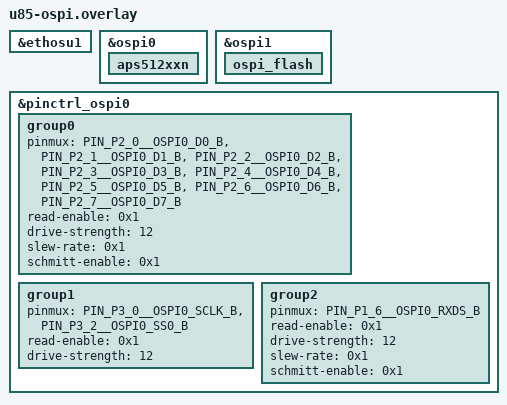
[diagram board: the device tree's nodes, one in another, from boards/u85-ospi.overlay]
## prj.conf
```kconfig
CONFIG_CPP=y
CONFIG_STD_CPP17=y
CONFIG_TENSORFLOW_LITE_MICRO=y
CONFIG_CMSIS_DSP=y
CONFIG_CMSIS_DSP_BASICMATH=y
CONFIG_CMSIS_DSP_COMPLEXMATH=y
CONFIG_CMSIS_DSP_TRANSFORM=y
CONFIG_ARM_ETHOS_U=y
CONFIG_HEAP_MEM_POOL_SIZE=16384
CONFIG_EVENTS=y

CONFIG_AUDIO=y
CONFIG_AUDIO_DMIC=y
CONFIG_TINYCRYPT=y
CONFIG_TINYCRYPT_SHA256=y

CONFIG_SERIAL=y
CONFIG_UART_INTERRUPT_DRIVEN=y
CONFIG_UART_LINE_CTRL=y
CONFIG_CONSOLE=y
CONFIG_UART_CONSOLE=y
CONFIG_PRINTK=y
CONFIG_LOG=y
CONFIG_LOG_MODE_IMMEDIATE=y
CONFIG_ARM_ETHOS_U_LOG_LEVEL_NONE=y

CONFIG_USB_DEVICE_STACK_NEXT=y
CONFIG_USBD_CDC_ACM_CLASS=y
CONFIG_USBD_LOG_LEVEL_WRN=y
CONFIG_UDC_DRIVER_LOG_LEVEL_WRN=y
CONFIG_USBD_CDC_ACM_LOG_LEVEL_ERR=y

CONFIG_BUILD_OUTPUT_HEX_GAP_FILL=n
CONFIG_BUILD_OUTPUT_S19_GAP_FILL=n

CONFIG_REQUIRES_FULL_LIBC=y
CONFIG_NEWLIB_LIBC=y
CONFIG_REQUIRES_FULL_LIBCPP=y
CONFIG_NEWLIB_LIBC_MIN_REQUIRED_HEAP_SIZE=8192
CONFIG_MAIN_STACK_SIZE=32768
```

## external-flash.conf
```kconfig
# Enable the frozen onboard ISSI driver/XIP initialization only.
CONFIG_FLASH=y
CONFIG_ALIF_OSPI_FLASH_XIP=y
```

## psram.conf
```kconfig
CONFIG_MEMC=y
CONFIG_MEMC_OSPI_ALIF=y
CONFIG_MEMC_ALIF_OSPI_APS512XXN=y
```

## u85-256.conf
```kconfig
CONFIG_ARM_ETHOS_U55_256=n
CONFIG_ARM_ETHOS_U85_256=y
```

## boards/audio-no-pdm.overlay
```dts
/* Build-only audio NONE personality: do not initialize the board PDM device. */
&pdm {
	status = "disabled";
};
```

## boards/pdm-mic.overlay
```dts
/*
 * Enable the pinned Alif PDM/DMIC peripheral for the DevKit microphone pair.
 * Channel selection remains an application-level contract.
 */
/ {
	aliases {
		pdm-audio = &pdm;
	};
};

&pdm {
	status = "okay";
};
```

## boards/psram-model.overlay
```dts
#include <zephyr/dt-bindings/memory-attr/memory-attr-arm.h>

/ {
	psram_model_memory: memory@a0000000 {
		compatible = "zephyr,memory-region";
		reg = <0xa0000000 0x04000000>;
		zephyr,memory-region = "PSRAM_MODEL";
		zephyr,memory-region-flags = "rw";
		zephyr,memory-attr = <DT_MEM_ARM_MPU_RAM_NOCACHE>;
	};
};
```

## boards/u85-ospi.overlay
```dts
/* Enable the on-board U85 and the OSPI devices required by the H1 image. */
&ethosu1 {
	status = "okay";
};

&ospi0 {
	status = "okay";
	aps512xxn {
		status = "okay";
	};
};

&ospi1 {
	status = "okay";
	ospi_flash {
		status = "okay";
	};
};

/* Copyright (C) Alif Semiconductor - All Rights Reserved.
 * Use, distribution and modification of this code is permitted under the
 * terms stated in the Alif Semiconductor Software License Agreement.
 *
 * Historical E8 DK PSRAM pin groups from the accepted ospi-psram snippet
 * (e8_dk_ospi0.overlay, SHA-256
 * 2add03d875047de8df6faa1a5b132625d34051ddc3e2ba87365804d300ab6d93).
 */
&pinctrl_ospi0 {
	group0 {
		pinmux = < PIN_P2_0__OSPI0_D0_B >,
			 < PIN_P2_1__OSPI0_D1_B >,
			 < PIN_P2_2__OSPI0_D2_B >,
			 < PIN_P2_3__OSPI0_D3_B >,
			 < PIN_P2_4__OSPI0_D4_B >,
			 < PIN_P2_5__OSPI0_D5_B >,
			 < PIN_P2_6__OSPI0_D6_B >,
			 < PIN_P2_7__OSPI0_D7_B >;
		read-enable = <0x1>;
		drive-strength = <12>;
		slew-rate = <0x1>;
		schmitt-enable = <0x1>;
	};
	group1 {
		pinmux = < PIN_P3_0__OSPI0_SCLK_B >,
			 < PIN_P3_2__OSPI0_SS0_B >;
		read-enable = <0x1>;
		drive-strength = <12>;
	};
	group2 {
		pinmux = < PIN_P1_6__OSPI0_RXDS_B >;
		read-enable = <0x1>;
		drive-strength = <12>;
		slew-rate = <0x1>;
		schmitt-enable = <0x1>;
	};
};
```

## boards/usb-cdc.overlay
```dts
/*
 * Native E8 USB-C application channel. This is the pinned sdk-alif CDC ACM
 * sample mechanism, with larger lossless application FIFOs.
 */
#include <dt-bindings/misc/alif_aipm_common.h>

&aipm_run_default {
	phy-pwr-gating = <ALIF_PHY_GATE_USB_MASK>;
};

ns: &ns {
	status = "okay";
};

zephyr_udc0: &usb {
	status = "okay";
};

&zephyr_udc0 {
	cdc_acm_uart0: cdc_acm_uart0 {
		compatible = "zephyr,cdc-acm-uart";
		label = "BirdNET H1 application channel";
		rx-fifo-size = <8192>;
		tx-fifo-size = <8192>;
		hw-flow-control;
	};
};
```

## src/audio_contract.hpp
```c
#pragma once

#include <cstddef>
#include <cstdint>

constexpr uint32_t H1_MIC_SAMPLE_RATE_HZ = 32000;
constexpr uint32_t H1_MIC_WINDOW_SAMPLES = 96000;
constexpr uint32_t H1_MIC_STRIDE_SAMPLES = 32000;
constexpr uint32_t H1_MIC_OVERLAP_SAMPLES = 64000;
constexpr uint32_t H1_MIC_RING_SAMPLES = 160000;
constexpr uint32_t H1_MIC_BLOCK_BYTES = 2048;
constexpr uint32_t H1_MIC_BLOCK_SAMPLES = H1_MIC_BLOCK_BYTES / sizeof(int16_t);
constexpr uint32_t H1_MIC_SLAB_BLOCKS = 8;
constexpr uint32_t H1_MIC_WINDOW_BYTES = H1_MIC_WINDOW_SAMPLES * sizeof(int16_t);
constexpr uint32_t H1_MIC_PCM_CHUNK_MAX_BYTES = 1024;
constexpr uint64_t H1_MIC_LATEST_WINDOW = UINT64_MAX;

static_assert(H1_MIC_WINDOW_SAMPLES == 3 * H1_MIC_SAMPLE_RATE_HZ);
static_assert(H1_MIC_STRIDE_SAMPLES == H1_MIC_SAMPLE_RATE_HZ);
static_assert(H1_MIC_WINDOW_SAMPLES - H1_MIC_STRIDE_SAMPLES ==
	      H1_MIC_OVERLAP_SAMPLES);
static_assert(H1_MIC_RING_SAMPLES >=
	      H1_MIC_WINDOW_SAMPLES + H1_MIC_STRIDE_SAMPLES);
static_assert(H1_MIC_BLOCK_BYTES % sizeof(int16_t) == 0);

enum class H1MicMode : uint32_t {
	Off = 0,
	CaptureOnly = 1,
	WindowValidate = 2,
	H1Single = 3,
};

enum class H1MicState : uint32_t {
	Off = 0,
	Starting = 1,
	Capture = 2,
	WindowReady = 3,
	Error = 4,
};

enum class H1MicInferenceState : uint32_t {
	Idle = 0,
	Running = 1,
	ResultReady = 2,
};

enum class H1MicError : int32_t {
	None = 0,
	NotInitialized = 1,
	AlreadyRunning = 2,
	InvalidMode = 3,
	TriggerStart = 4,
	TriggerStop = 5,
	ReadTimeout = 6,
	ReadFailure = 7,
	InvalidBlockSize = 8,
	Fifo = 9,
	SlabExhausted = 10,
	DriverQueueOverrun = 11,
	Sequence = 12,
	RingFrontier = 13,
	NoCompleteWindow = 14,
	WindowNotRetained = 15,
	ModeDisallowsOperation = 16,
	NoSelectedWindow = 17,
};

struct H1PcmStatistics {
	uint64_t sampleCount;
	int16_t minimum;
	int16_t maximum;
	int64_t sum;
	uint64_t sumSquares;
	uint64_t positiveClippingCount;
	uint64_t negativeClippingCount;
	uint64_t zeroCount;
	uint32_t maximumAdjacentJump;
};

struct H1SelectedWindowInfo {
	bool valid;
	uint64_t sequence;
	uint64_t startSample;
	uint64_t endSample;
	uint32_t physicalStartIndex;
	bool wraps;
	uint32_t crc32;
	char sha256[65];
	H1PcmStatistics statistics;
};

struct H1MicStatusSnapshot {
	bool initialized;
	bool running;
	H1MicMode mode;
	H1MicState state;
	H1MicInferenceState inferenceState;
	H1MicError lastError;
	int32_t initStatus;
	int32_t lastDriverStatus;
	uint64_t driverPublishedBlocks;
	uint64_t consumedBlocks;
	uint64_t expectedSequence;
	uint64_t sequenceFaults;
	uint64_t fifoErrors;
	uint64_t slabMisses;
	uint64_t driverQueueOverruns;
	uint64_t readTimeouts;
	uint64_t invalidBlockSizes;
	uint32_t queueOccupancy;
	uint32_t queueHighWater;
	uint32_t slabUsed;
	uint32_t slabHighWater;
	uint64_t firstPublishCycles;
	uint64_t lastPublishCycles;
	uint32_t timingClockHz;
	uint64_t totalSamplesCommitted;
	uint64_t oldestRetainedSample;
	uint32_t ringWriteIndex;
	uint64_t ringFrontierFaults;
	uint64_t completeWindows;
	uint64_t latestWindowSequence;
	uint64_t latestWindowStartSample;
	uint64_t latestWindowEndSample;
	uint64_t windowGeometryFaults;
	H1PcmStatistics captureStatistics;
	H1SelectedWindowInfo selectedWindow;
};

const char *h1MicModeName(H1MicMode mode);
const char *h1MicStateName(H1MicState state);
const char *h1MicInferenceStateName(H1MicInferenceState state);
const char *h1MicErrorName(H1MicError error);
```

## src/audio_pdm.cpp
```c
#include "audio_pdm.hpp"

#include "audio_pdm_driver_hooks.h"
#include "model_storage.hpp"
#include "pcm_ring.hpp"
#include "run_state.hpp"
#include "sha256.hpp"
#include "sliding_window.hpp"

#include <cerrno>
#include <climits>
#include <cstddef>
#include <cstdint>
#include <cstring>

#include <zephyr/audio/dmic.h>
#include <zephyr/device.h>
#include <zephyr/devicetree.h>
#include <zephyr/drivers/pdm/pdm_alif.h>
#include <zephyr/kernel.h>
#include <zephyr/sys/atomic.h>
#include <zephyr/sys/time_units.h>

namespace {
constexpr uint8_t kChannel = 4;
constexpr uint32_t kChannelMap = PDM_MASK_CHANNEL_4;
constexpr uint32_t kPhase = 0x0000001f;
constexpr uint32_t kGain = 0x0000000d;
constexpr uint32_t kPeakDetectThreshold = 0x00060002;
constexpr uint32_t kPeakDetectInterval = 0x0004002d;
constexpr uint32_t kIirCoefficient = 0x00000004;
constexpr int32_t kReadTimeoutMs = 500;
constexpr size_t kThreadStackBytes = 4096;

constexpr uint32_t kFirCoefficients[PDM_MAX_FIR_COEFFICIENT] = {
	0x00000001, 0x00000003, 0x00000003, 0x000007f4, 0x00000004,
	0x000007ed, 0x000007f5, 0x000007f4, 0x000007d3, 0x000007fe,
	0x000007bc, 0x000007e5, 0x000007d9, 0x00000793, 0x00000029,
	0x0000072c, 0x00000072, 0x000002fd,
};

#define H1_PDM_NODE DT_ALIAS(pdm_audio)
BUILD_ASSERT(DT_NODE_HAS_STATUS(H1_PDM_NODE, okay),
	     "The PDM microphone devicetree alias must be enabled");

const device *const kPdm = DEVICE_DT_GET(H1_PDM_NODE);

k_mem_slab gPdmSlab;
__attribute__((section("SRAM1.audio"), aligned(32)))
uint8_t gPdmSlabBuffer[H1_MIC_BLOCK_BYTES * H1_MIC_SLAB_BLOCKS];
K_THREAD_STACK_DEFINE(gCaptureStack, kThreadStackBytes);
K_SEM_DEFINE(gCaptureStart, 0, 1);
K_SEM_DEFINE(gCaptureStopped, 0, 1);
K_MUTEX_DEFINE(gAudioMutex);

k_thread gCaptureThread;
atomic_t gRunRequested;
atomic_t gThreadActive;
bool gThreadCreated;
bool gInitialized;
int32_t gInitStatus = -EAGAIN;
int32_t gLastDriverStatus;
H1MicMode gMode = H1MicMode::Off;
H1MicState gState = H1MicState::Off;
H1MicInferenceState gInferenceState = H1MicInferenceState::Idle;
H1MicError gLastError = H1MicError::None;
uint64_t gConsumedBlocks;
uint64_t gExpectedSequence;
uint64_t gSequenceFaults;
uint64_t gReadTimeouts;
uint64_t gInvalidBlockSizes;
uint32_t gSlabHighWater;
H1PcmStatistics gCaptureStatistics;
bool gHavePreviousSample;
int16_t gPreviousSample;
H1SelectedWindowInfo gSelectedWindow;

k_spinlock gDriverLock;
H1PdmDriverTelemetry gDriverTelemetry;

H1PcmRing &ring()
{
	static H1PcmRing instance(h1PcmRingStorage(), H1_MIC_RING_SAMPLES);
	return instance;
}

H1SlidingWindowTracker &windows()
{
	static H1SlidingWindowTracker instance(H1_MIC_WINDOW_SAMPLES,
					       H1_MIC_STRIDE_SAMPLES);
	return instance;
}

uint32_t crc32(const uint8_t *data, size_t bytes)
{
	uint32_t crc = UINT32_C(0xffffffff);
	for (size_t index = 0; index < bytes; ++index) {
		crc ^= data[index];
		for (unsigned bit = 0; bit < 8; ++bit) {
			crc = (crc >> 1) ^
			      (UINT32_C(0xedb88320) & (0u - (crc & 1u)));
		}
	}
	return ~crc;
}

void resetStatistics(H1PcmStatistics &statistics)
{
	memset(&statistics, 0, sizeof(statistics));
	statistics.minimum = INT16_MAX;
	statistics.maximum = INT16_MIN;
}

H1PcmStatistics reportableStatistics(H1PcmStatistics statistics)
{
	if (statistics.sampleCount == 0) {
		statistics.minimum = 0;
		statistics.maximum = 0;
	}
	return statistics;
}

void updateStatistics(H1PcmStatistics &statistics, const int16_t *samples,
		      uint32_t count, bool &havePrevious, int16_t &previous)
{
	for (uint32_t index = 0; index < count; ++index) {
		const int16_t sample = samples[index];
		if (sample < statistics.minimum) {
			statistics.minimum = sample;
		}
		if (sample > statistics.maximum) {
			statistics.maximum = sample;
		}
		statistics.sum += sample;
		const int64_t extended = sample;
		statistics.sumSquares += uint64_t(extended * extended);
		statistics.positiveClippingCount += sample == INT16_MAX;
		statistics.negativeClippingCount += sample == INT16_MIN;
		statistics.zeroCount += sample == 0;
		if (havePrevious) {
			int32_t jump = int32_t(sample) - int32_t(previous);
			if (jump < 0) {
				jump = -jump;
			}
			if (uint32_t(jump) > statistics.maximumAdjacentJump) {
				statistics.maximumAdjacentJump = uint32_t(jump);
			}
		}
		previous = sample;
		havePrevious = true;
		++statistics.sampleCount;
	}
}

H1PcmStatistics calculateStatistics(const int16_t *samples, uint32_t count)
{
	H1PcmStatistics statistics;
	resetStatistics(statistics);
	bool havePrevious = false;
	int16_t previous = 0;
	updateStatistics(statistics, samples, count, havePrevious, previous);
	return reportableStatistics(statistics);
}

void setStateError(H1MicError error, int32_t driverStatus)
{
	k_mutex_lock(&gAudioMutex, K_FOREVER);
	gLastError = error;
	gLastDriverStatus = driverStatus;
	gState = H1MicState::Error;
	k_mutex_unlock(&gAudioMutex);
}

bool driverFault(H1MicError &error)
{
	H1PdmDriverTelemetry telemetry{};
	h1PdmDriverTelemetryGet(&telemetry);
	if (telemetry.fifo_errors != 0) {
		error = H1MicError::Fifo;
		return true;
	}
	if (telemetry.slab_misses != 0) {
		error = H1MicError::SlabExhausted;
		return true;
	}
	if (telemetry.queue_overruns != 0) {
		error = H1MicError::DriverQueueOverrun;
		return true;
	}
	return false;
}

void finishCaptureThread()
{
	atomic_clear(&gThreadActive);
	k_sem_give(&gCaptureStopped);
}

void failCapture(H1MicError error, int32_t driverStatus)
{
	atomic_clear(&gRunRequested);
	setStateError(error, driverStatus);
	(void)dmic_trigger(kPdm, DMIC_TRIGGER_STOP);
	finishCaptureThread();
}

void captureThread(void *, void *, void *)
{
	for (;;) {
		k_sem_take(&gCaptureStart, K_FOREVER);
		while (atomic_get(&gRunRequested) != 0) {
			void *buffer = nullptr;
			size_t bytes = 0;
			const int status = dmic_read(kPdm, 0, &buffer, &bytes,
						     kReadTimeoutMs);
			if (status != 0) {
				if (atomic_get(&gRunRequested) == 0) {
					break;
				}
				H1MicError error = H1MicError::ReadFailure;
				if (status == -EAGAIN || status == -ETIMEDOUT) {
					k_mutex_lock(&gAudioMutex, K_FOREVER);
					++gReadTimeouts;
					k_mutex_unlock(&gAudioMutex);
					error = H1MicError::ReadTimeout;
				}
				H1MicError hookError = H1MicError::None;
				if (driverFault(hookError)) {
					error = hookError;
				}
				failCapture(error, status);
				goto next_start;
			}
			if (atomic_get(&gRunRequested) == 0) {
				k_mem_slab_free(&gPdmSlab, buffer);
				break;
			}
			if (bytes != H1_MIC_BLOCK_BYTES || buffer == nullptr) {
				k_mutex_lock(&gAudioMutex, K_FOREVER);
				++gInvalidBlockSizes;
				k_mutex_unlock(&gAudioMutex);
				if (buffer != nullptr) {
					k_mem_slab_free(&gPdmSlab, buffer);
				}
				failCapture(H1MicError::InvalidBlockSize, -EMSGSIZE);
				goto next_start;
			}

			H1MicError hookError = H1MicError::None;
			if (driverFault(hookError)) {
				k_mem_slab_free(&gPdmSlab, buffer);
				failCapture(hookError, -EIO);
				goto next_start;
			}

			H1PdmDriverTelemetry driver{};
			h1PdmDriverTelemetryGet(&driver);
			k_mutex_lock(&gAudioMutex, K_FOREVER);
			const uint64_t sequence = gConsumedBlocks;
			if (driver.published_blocks <= sequence ||
			    sequence != gExpectedSequence) {
				++gSequenceFaults;
				k_mutex_unlock(&gAudioMutex);
				k_mem_slab_free(&gPdmSlab, buffer);
				failCapture(H1MicError::Sequence, -EILSEQ);
				goto next_start;
			}
			const auto *samples = static_cast<const int16_t *>(buffer);
			if (!ring().commit(samples, H1_MIC_BLOCK_SAMPLES)) {
				k_mutex_unlock(&gAudioMutex);
				k_mem_slab_free(&gPdmSlab, buffer);
				failCapture(H1MicError::RingFrontier, -ENOSPC);
				goto next_start;
			}
			updateStatistics(gCaptureStatistics, samples, H1_MIC_BLOCK_SAMPLES,
					 gHavePreviousSample, gPreviousSample);
			windows().observe(ring().totalSamples());
			++gConsumedBlocks;
			++gExpectedSequence;
			const uint32_t slabUsed = k_mem_slab_num_used_get(&gPdmSlab);
			if (slabUsed > gSlabHighWater) {
				gSlabHighWater = slabUsed;
			}
			if (gMode != H1MicMode::CaptureOnly &&
			    windows().hasCompleteWindow()) {
				gState = H1MicState::WindowReady;
			}
			gLastDriverStatus = 0;
			k_mutex_unlock(&gAudioMutex);
			k_mem_slab_free(&gPdmSlab, buffer);
		}
		finishCaptureThread();
next_start:
		;
	}
}

int configurePdm()
{
	if (!device_is_ready(kPdm)) {
		return -ENODEV;
	}
	pcm_stream_cfg stream{};
	dmic_cfg config{};
	stream.pcm_width = 16;
	stream.mem_slab = &gPdmSlab;
	stream.block_size = H1_MIC_BLOCK_BYTES;
	config.streams = &stream;
	config.channel.req_num_streams = 1;
	config.channel.req_num_chan = 1;
	config.channel.req_chan_map_lo = kChannelMap;
	const int status = dmic_configure(kPdm, &config);
	if (status != 0) {
		return status;
	}

	pdm_set_ch_phase(kPdm, kChannel, kPhase);
	pdm_set_ch_gain(kPdm, kChannel, kGain);
	pdm_set_peak_detect_th(kPdm, kChannel, kPeakDetectThreshold);
	pdm_set_peak_detect_itv(kPdm, kChannel, kPeakDetectInterval);
	pdm_ch_config channel{};
	channel.ch_num = kChannel;
	memcpy(channel.ch_fir_coef, kFirCoefficients,
	       sizeof(channel.ch_fir_coef));
	channel.ch_iir_coef = kIirCoefficient;
	pdm_channel_config(kPdm, &channel);
	pdm_mode(kPdm, PDM_MODE_WIDE_BANDWIDTH_AUDIO_1536_CLK_FRQ);
	return 0;
}
} // namespace

extern "C" void h1PdmDriverTelemetryReset(void)
{
	k_spinlock_key_t key = k_spin_lock(&gDriverLock);
	memset(&gDriverTelemetry, 0, sizeof(gDriverTelemetry));
	k_spin_unlock(&gDriverLock, key);
}

extern "C" void h1PdmDriverBlockPublished(uint32_t queueOccupancy)
{
	const uint64_t now = k_cycle_get_64();
	k_spinlock_key_t key = k_spin_lock(&gDriverLock);
	if (gDriverTelemetry.published_blocks == 0) {
		gDriverTelemetry.first_publish_cycles = now;
	}
	++gDriverTelemetry.published_blocks;
	gDriverTelemetry.last_publish_cycles = now;
	gDriverTelemetry.queue_occupancy = queueOccupancy;
	if (queueOccupancy > gDriverTelemetry.queue_high_water) {
		gDriverTelemetry.queue_high_water = queueOccupancy;
	}
	k_spin_unlock(&gDriverLock, key);
}

extern "C" void h1PdmDriverFifoError(void)
{
	k_spinlock_key_t key = k_spin_lock(&gDriverLock);
	++gDriverTelemetry.fifo_errors;
	k_spin_unlock(&gDriverLock, key);
}

extern "C" void h1PdmDriverSlabMiss(void)
{
	k_spinlock_key_t key = k_spin_lock(&gDriverLock);
	++gDriverTelemetry.slab_misses;
	k_spin_unlock(&gDriverLock, key);
}

extern "C" void h1PdmDriverQueueOverrun(void)
{
	k_spinlock_key_t key = k_spin_lock(&gDriverLock);
	++gDriverTelemetry.queue_overruns;
	k_spin_unlock(&gDriverLock, key);
}

extern "C" void h1PdmDriverTelemetryGet(H1PdmDriverTelemetry *telemetry)
{
	if (!telemetry) {
		return;
	}
	k_spinlock_key_t key = k_spin_lock(&gDriverLock);
	*telemetry = gDriverTelemetry;
	k_spin_unlock(&gDriverLock, key);
}

int h1AudioPdmInit()
{
	if (gInitialized) {
		return gInitStatus;
	}
	gInitStatus = k_mem_slab_init(&gPdmSlab, gPdmSlabBuffer,
				      H1_MIC_BLOCK_BYTES, H1_MIC_SLAB_BLOCKS);
	if (gInitStatus == 0) {
		gInitStatus = configurePdm();
	}
	if (gInitStatus != 0) {
		gLastDriverStatus = gInitStatus;
		gLastError = H1MicError::NotInitialized;
		gState = H1MicState::Error;
		return gInitStatus;
	}
	ring().reset();
	windows().reset();
	resetStatistics(gCaptureStatistics);
	memset(&gSelectedWindow, 0, sizeof(gSelectedWindow));
	h1PdmDriverTelemetryReset();
	if (!gThreadCreated) {
		k_thread_create(&gCaptureThread, gCaptureStack,
				K_THREAD_STACK_SIZEOF(gCaptureStack), captureThread,
				nullptr, nullptr, nullptr, K_PRIO_COOP(1), 0,
				K_NO_WAIT);
		k_thread_name_set(&gCaptureThread, "h1_audio_producer");
		gThreadCreated = true;
	}
	gInitialized = true;
	gLastError = H1MicError::None;
	gState = H1MicState::Off;
	return 0;
}

bool h1AudioPdmStart(H1MicMode mode, H1MicError &error)
{
	error = H1MicError::None;
	if (!gInitialized) {
		error = H1MicError::NotInitialized;
		return false;
	}
	if (mode != H1MicMode::CaptureOnly &&
	    mode != H1MicMode::WindowValidate &&
	    mode != H1MicMode::H1Single) {
		error = H1MicError::InvalidMode;
		return false;
	}
	k_mutex_lock(&gAudioMutex, K_FOREVER);
	if (gState != H1MicState::Off || atomic_get(&gThreadActive) != 0) {
		k_mutex_unlock(&gAudioMutex);
		error = H1MicError::AlreadyRunning;
		return false;
	}
	ring().reset();
	windows().reset();
	resetStatistics(gCaptureStatistics);
	gHavePreviousSample = false;
	gPreviousSample = 0;
	memset(&gSelectedWindow, 0, sizeof(gSelectedWindow));
	gConsumedBlocks = 0;
	gExpectedSequence = 0;
	gSequenceFaults = 0;
	gReadTimeouts = 0;
	gInvalidBlockSizes = 0;
	gSlabHighWater = 0;
	gMode = mode;
	gState = H1MicState::Starting;
	gInferenceState = H1MicInferenceState::Idle;
	gLastError = H1MicError::None;
	gLastDriverStatus = 0;
	k_mutex_unlock(&gAudioMutex);
	h1PdmDriverTelemetryReset();
	while (k_sem_take(&gCaptureStopped, K_NO_WAIT) == 0) {
	}
	atomic_set(&gRunRequested, 1);
	atomic_set(&gThreadActive, 1);
	const int status = dmic_trigger(kPdm, DMIC_TRIGGER_START);
	if (status != 0) {
		atomic_clear(&gRunRequested);
		atomic_clear(&gThreadActive);
		setStateError(H1MicError::TriggerStart, status);
		error = H1MicError::TriggerStart;
		return false;
	}
	k_mutex_lock(&gAudioMutex, K_FOREVER);
	gState = H1MicState::Capture;
	k_mutex_unlock(&gAudioMutex);
	k_sem_give(&gCaptureStart);
	return true;
}

bool h1AudioPdmStop(H1MicError &error)
{
	error = H1MicError::None;
	if (!gInitialized) {
		error = H1MicError::NotInitialized;
		return false;
	}
	const bool active = atomic_get(&gThreadActive) != 0;
	atomic_clear(&gRunRequested);
	int status = 0;
	if (active) {
		status = dmic_trigger(kPdm, DMIC_TRIGGER_STOP);
		if (k_sem_take(&gCaptureStopped, K_MSEC(1500)) != 0 && status == 0) {
			status = -ETIMEDOUT;
		}
	}
	k_mutex_lock(&gAudioMutex, K_FOREVER);
	if (status == 0) {
		gState = H1MicState::Off;
	} else {
		gState = H1MicState::Error;
		gLastError = H1MicError::TriggerStop;
		gLastDriverStatus = status;
		error = H1MicError::TriggerStop;
	}
	k_mutex_unlock(&gAudioMutex);
	return status == 0;
}

H1MicStatusSnapshot h1AudioPdmStatus()
{
	H1MicStatusSnapshot snapshot{};
	k_mutex_lock(&gAudioMutex, K_FOREVER);
	snapshot.initialized = gInitialized;
	snapshot.running = atomic_get(&gRunRequested) != 0;
	snapshot.mode = gMode;
	snapshot.state = gState;
	snapshot.inferenceState = gInferenceState;
	snapshot.lastError = gLastError;
	snapshot.initStatus = gInitStatus;
	snapshot.lastDriverStatus = gLastDriverStatus;
	snapshot.consumedBlocks = gConsumedBlocks;
	snapshot.expectedSequence = gExpectedSequence;
	snapshot.sequenceFaults = gSequenceFaults;
	snapshot.readTimeouts = gReadTimeouts;
	snapshot.invalidBlockSizes = gInvalidBlockSizes;
	snapshot.slabUsed = k_mem_slab_num_used_get(&gPdmSlab);
	snapshot.slabHighWater = gSlabHighWater;
	snapshot.totalSamplesCommitted = ring().totalSamples();
	snapshot.oldestRetainedSample = ring().oldestRetainedSample();
	snapshot.ringWriteIndex = ring().writeIndex();
	snapshot.ringFrontierFaults = ring().frontierFaults();
	snapshot.completeWindows = windows().completeWindows();
	snapshot.latestWindowSequence = windows().latestSequence();
	snapshot.latestWindowStartSample = windows().latestStartSample();
	snapshot.latestWindowEndSample = windows().latestEndSample();
	snapshot.windowGeometryFaults = windows().geometryFaults();
	snapshot.captureStatistics = reportableStatistics(gCaptureStatistics);
	snapshot.selectedWindow = gSelectedWindow;
	k_mutex_unlock(&gAudioMutex);

	H1PdmDriverTelemetry driver{};
	h1PdmDriverTelemetryGet(&driver);
	snapshot.driverPublishedBlocks = driver.published_blocks;
	snapshot.fifoErrors = driver.fifo_errors;
	snapshot.slabMisses = driver.slab_misses;
	snapshot.driverQueueOverruns = driver.queue_overruns;
	snapshot.firstPublishCycles = driver.first_publish_cycles;
	snapshot.lastPublishCycles = driver.last_publish_cycles;
	snapshot.queueOccupancy =
		driver.published_blocks >= snapshot.consumedBlocks
			? uint32_t(driver.published_blocks - snapshot.consumedBlocks)
			: 0;
	snapshot.queueHighWater = driver.queue_high_water;
	snapshot.timingClockHz = uint32_t(sys_clock_hw_cycles_per_sec());
	return snapshot;
}

bool h1AudioPdmSelectWindow(uint64_t sequence, H1SelectedWindowInfo &info,
			    H1MicError &error)
{
	error = H1MicError::None;
	k_mutex_lock(&gAudioMutex, K_FOREVER);
	if (gMode != H1MicMode::WindowValidate && gMode != H1MicMode::H1Single) {
		k_mutex_unlock(&gAudioMutex);
		error = H1MicError::ModeDisallowsOperation;
		return false;
	}
	if (!windows().hasCompleteWindow()) {
		k_mutex_unlock(&gAudioMutex);
		error = H1MicError::NoCompleteWindow;
		return false;
	}
	if (sequence == H1_MIC_LATEST_WINDOW) {
		sequence = windows().latestSequence();
	}
	uint64_t start = 0;
	uint64_t end = 0;
	if (!windows().bounds(sequence, start, end) ||
	    start < ring().oldestRetainedSample()) {
		k_mutex_unlock(&gAudioMutex);
		error = H1MicError::WindowNotRetained;
		return false;
	}
	H1SelectedWindowInfo selected{};
	selected.valid = true;
	selected.sequence = sequence;
	selected.startSample = start;
	selected.endSample = end;
	selected.physicalStartIndex = ring().physicalIndex(start);
	selected.wraps = ring().rangeWraps(start, H1_MIC_WINDOW_SAMPLES);
	ring().beginConsumer(start);
	const bool copied = ring().copyRange(start, H1_MIC_WINDOW_SAMPLES,
					     h1SelectedPcmWindow());
	ring().endConsumer();
	if (!copied) {
		k_mutex_unlock(&gAudioMutex);
		error = H1MicError::WindowNotRetained;
		return false;
	}
	gSelectedWindow.valid = false;
	k_mutex_unlock(&gAudioMutex);

	selected.crc32 = crc32(
		reinterpret_cast<const uint8_t *>(h1SelectedPcmWindow()),
		H1_MIC_WINDOW_BYTES);
	h1Sha256Hex(h1SelectedPcmWindow(), H1_MIC_WINDOW_BYTES,
		    selected.sha256);
	if (selected.sha256[0] == '\0') {
		error = H1MicError::ReadFailure;
		return false;
	}
	selected.statistics =
		calculateStatistics(h1SelectedPcmWindow(), H1_MIC_WINDOW_SAMPLES);

	k_mutex_lock(&gAudioMutex, K_FOREVER);
	gSelectedWindow = selected;
	info = selected;
	k_mutex_unlock(&gAudioMutex);
	return true;
}

bool h1AudioPdmCopySelectedBytes(uint32_t offsetBytes, void *destination,
				 uint32_t bytes, H1MicError &error)
{
	error = H1MicError::None;
	if (!destination || bytes == 0 || bytes > H1_MIC_PCM_CHUNK_MAX_BYTES ||
	    offsetBytes > H1_MIC_WINDOW_BYTES ||
	    bytes > H1_MIC_WINDOW_BYTES - offsetBytes) {
		error = H1MicError::WindowNotRetained;
		return false;
	}
	k_mutex_lock(&gAudioMutex, K_FOREVER);
	if (!gSelectedWindow.valid) {
		k_mutex_unlock(&gAudioMutex);
		error = H1MicError::NoSelectedWindow;
		return false;
	}
	memcpy(destination,
	       reinterpret_cast<const uint8_t *>(h1SelectedPcmWindow()) + offsetBytes,
	       bytes);
	k_mutex_unlock(&gAudioMutex);
	return true;
}

bool h1AudioPdmPrepareSelectedWaveform(float *destination, size_t elements,
				       const H1WaveformToken &token,
				       uint32_t &floatCrc32,
				       char floatSha256[65],
				       H1SelectedWindowInfo &info,
				       H1MicError &error)
{
	error = H1MicError::None;
	h1RunStateMark(H1RunState::MicWindowResolveBegin);
	if (!destination || !floatSha256 || elements != H1_MIC_WINDOW_SAMPLES ||
	    !h1WaveformLifecycle.canWrite(token, destination) ||
	    h1WaveformLifecycle.producer != H1WaveformProducer::Pdm) {
		error = H1MicError::InvalidBlockSize;
		return false;
	}
	k_mutex_lock(&gAudioMutex, K_FOREVER);
	if (gMode != H1MicMode::H1Single) {
		k_mutex_unlock(&gAudioMutex);
		error = H1MicError::ModeDisallowsOperation;
		return false;
	}
	if (!gSelectedWindow.valid) {
		k_mutex_unlock(&gAudioMutex);
		error = H1MicError::NoSelectedWindow;
		return false;
	}
	h1RunStateSetWindow(gSelectedWindow.sequence);
	h1RunStateMark(H1RunState::MicWindowResolveDone);
	const int16_t *source = h1SelectedPcmWindow();
	h1RunStateMark(H1RunState::MicPcmToFloatBegin);
	for (size_t index = 0; index < elements; ++index) {
		destination[index] = float(source[index]) * (1.0f / 32768.0f);
	}
	const size_t bytes = elements * sizeof(float);
	h1WaveformLifecycle.noteResidentCrc(uint32_t(bytes));
	floatCrc32 = crc32(reinterpret_cast<const uint8_t *>(destination), bytes);
	h1Sha256Hex(destination, bytes, floatSha256);
	info = gSelectedWindow;
	k_mutex_unlock(&gAudioMutex);
	h1RunStateSetWaveform(destination, elements, floatCrc32, floatSha256,
			      info.statistics.minimum, info.statistics.maximum);
	h1RunStateMark(H1RunState::MicPcmToFloatDone);
	return true;
}

void h1AudioPdmSetInferenceState(H1MicInferenceState state)
{
	k_mutex_lock(&gAudioMutex, K_FOREVER);
	gInferenceState = state;
	k_mutex_unlock(&gAudioMutex);
}

const char *h1MicModeName(H1MicMode mode)
{
	switch (mode) {
	case H1MicMode::Off:
		return "MIC_OFF";
	case H1MicMode::CaptureOnly:
		return "MIC_CAPTURE_ONLY";
	case H1MicMode::WindowValidate:
		return "MIC_WINDOW_VALIDATE";
	case H1MicMode::H1Single:
		return "MIC_H1_SINGLE";
	}
	return "MIC_MODE_UNKNOWN";
}

const char *h1MicStateName(H1MicState state)
{
	switch (state) {
	case H1MicState::Off:
		return "MIC_OFF";
	case H1MicState::Starting:
		return "MIC_STARTING";
	case H1MicState::Capture:
		return "MIC_CAPTURE";
	case H1MicState::WindowReady:
		return "MIC_WINDOW_READY";
	case H1MicState::Error:
		return "MIC_ERROR";
	}
	return "MIC_STATE_UNKNOWN";
}

const char *h1MicInferenceStateName(H1MicInferenceState state)
{
	switch (state) {
	case H1MicInferenceState::Idle:
		return "H1_IDLE";
	case H1MicInferenceState::Running:
		return "H1_RUNNING";
	case H1MicInferenceState::ResultReady:
		return "H1_RESULT_READY";
	}
	return "H1_STATE_UNKNOWN";
}

const char *h1MicErrorName(H1MicError error)
{
	switch (error) {
	case H1MicError::None:
		return "NONE";
	case H1MicError::NotInitialized:
		return "NOT_INITIALIZED";
	case H1MicError::AlreadyRunning:
		return "ALREADY_RUNNING";
	case H1MicError::InvalidMode:
		return "INVALID_MODE";
	case H1MicError::TriggerStart:
		return "TRIGGER_START";
	case H1MicError::TriggerStop:
		return "TRIGGER_STOP";
	case H1MicError::ReadTimeout:
		return "READ_TIMEOUT";
	case H1MicError::ReadFailure:
		return "READ_FAILURE";
	case H1MicError::InvalidBlockSize:
		return "INVALID_BLOCK_SIZE";
	case H1MicError::Fifo:
		return "PDM_FIFO";
	case H1MicError::SlabExhausted:
		return "SLAB_EXHAUSTED";
	case H1MicError::DriverQueueOverrun:
		return "DRIVER_QUEUE_OVERRUN";
	case H1MicError::Sequence:
		return "SEQUENCE";
	case H1MicError::RingFrontier:
		return "RING_FRONTIER";
	case H1MicError::NoCompleteWindow:
		return "NO_COMPLETE_WINDOW";
	case H1MicError::WindowNotRetained:
		return "WINDOW_NOT_RETAINED";
	case H1MicError::ModeDisallowsOperation:
		return "MODE_DISALLOWS_OPERATION";
	case H1MicError::NoSelectedWindow:
		return "NO_SELECTED_WINDOW";
	}
	return "UNKNOWN";
}
```

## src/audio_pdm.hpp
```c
#pragma once

#include "waveform_lifecycle.hpp"

#include "audio_contract.hpp"

#include <cstddef>
#include <cstdint>

int h1AudioPdmInit();
bool h1AudioPdmStart(H1MicMode mode, H1MicError &error);
bool h1AudioPdmStop(H1MicError &error);
H1MicStatusSnapshot h1AudioPdmStatus();
bool h1AudioPdmSelectWindow(uint64_t sequence, H1SelectedWindowInfo &info,
			    H1MicError &error);
bool h1AudioPdmCopySelectedBytes(uint32_t offsetBytes, void *destination,
				 uint32_t bytes, H1MicError &error);
bool h1AudioPdmPrepareSelectedWaveform(float *destination, size_t elements,
				       const H1WaveformToken &token,
				       uint32_t &floatCrc32,
				       char floatSha256[65],
				       H1SelectedWindowInfo &info,
				       H1MicError &error);
void h1AudioPdmSetInferenceState(H1MicInferenceState state);
```

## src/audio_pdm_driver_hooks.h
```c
#pragma once

#include <stdint.h>

#ifdef __cplusplus
extern "C" {
#endif

struct H1PdmDriverTelemetry {
	uint64_t published_blocks;
	uint64_t fifo_errors;
	uint64_t slab_misses;
	uint64_t queue_overruns;
	uint64_t first_publish_cycles;
	uint64_t last_publish_cycles;
	uint32_t queue_occupancy;
	uint32_t queue_high_water;
};

void h1PdmDriverTelemetryReset(void);
void h1PdmDriverBlockPublished(uint32_t queue_occupancy);
void h1PdmDriverFifoError(void);
void h1PdmDriverSlabMiss(void);
void h1PdmDriverQueueOverrun(void);
void h1PdmDriverTelemetryGet(struct H1PdmDriverTelemetry *telemetry);

#ifdef __cplusplus
}
#endif
```

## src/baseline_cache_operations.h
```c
// SPDX-FileCopyrightText: 2026 Taras Kuchynskyy
// SPDX-License-Identifier: Apache-2.0
#pragma once
#include "baseline_profile.h"

/* Branch-observed diagnostic operation masks only. The real production cache
 * callback API and its CMSIS operation arguments are unchanged. */

static inline struct H1BaselineCache *h1BaselineCleanRange(uint32_t *address, uint32_t bytes)
{
 const uint32_t operation_mask = H1_BASELINE_CACHE_CLEAN | H1_BASELINE_CACHE_RANGE;
 return h1BaselineCacheBegin(address, bytes, operation_mask, H1_EVENT_PRE_SUBMIT_CACHE_BEGIN);
}

static inline struct H1BaselineCache *h1BaselineCleanWhole(uint32_t *address, uint32_t bytes)
{
 const uint32_t operation_mask = H1_BASELINE_CACHE_CLEAN | H1_BASELINE_CACHE_WHOLE;
 return h1BaselineCacheBegin(address, bytes, operation_mask, H1_EVENT_PRE_SUBMIT_CACHE_BEGIN);
}

static inline struct H1BaselineCache *h1BaselineFlushBarrier(uint32_t *address, uint32_t bytes)
{
 const uint32_t operation_mask = H1_BASELINE_CACHE_BARRIER;
 return h1BaselineCacheBegin(address, bytes, operation_mask, H1_EVENT_PRE_SUBMIT_CACHE_BEGIN);
}

static inline struct H1BaselineCache *h1BaselineInvalidateRange(uint32_t *address, uint32_t bytes)
{
 const uint32_t operation_mask = H1_BASELINE_CACHE_INVALIDATE | H1_BASELINE_CACHE_RANGE;
 return h1BaselineCacheBegin(address, bytes, operation_mask, H1_EVENT_WAIT_CACHE_BEGIN);
}

static inline struct H1BaselineCache *h1BaselineCleanInvalidateWhole(uint32_t *address, uint32_t bytes)
{
 const uint32_t operation_mask = H1_BASELINE_CACHE_CLEAN | H1_BASELINE_CACHE_INVALIDATE | H1_BASELINE_CACHE_WHOLE;
 return h1BaselineCacheBegin(address, bytes, operation_mask, H1_EVENT_WAIT_CACHE_BEGIN);
}

static inline struct H1BaselineCache *h1BaselineInvalidateBarrier(uint32_t *address, uint32_t bytes)
{
 const uint32_t operation_mask = H1_BASELINE_CACHE_BARRIER;
 return h1BaselineCacheBegin(address, bytes, operation_mask, H1_EVENT_WAIT_CACHE_BEGIN);
}
```

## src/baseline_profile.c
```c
// SPDX-FileCopyrightText: 2026 Taras Kuchynskyy
// SPDX-License-Identifier: Apache-2.0
#include "baseline_profile.h"
#include "lifecycle_reuse.h"
#ifndef ETHOSU85
#define ETHOSU85 1
#endif
#include <ethosu_driver.h>
#include <pmu_ethosu.h>
#include <cmsis_core.h>
#include <stddef.h>
#include <string.h>
#include <zephyr/kernel.h>
#include <zephyr/sys_clock.h>
#if !defined(CONFIG_TIMER_HAS_64BIT_CYCLE_COUNTER) || !defined(CONFIG_CORTEX_M_SYSTICK_64BIT_CYCLE_COUNTER)
#error "Frozen baseline requires configured 64-bit SysTick cycle extension"
#endif
#if CONFIG_SYS_CLOCK_HW_CYCLES_PER_SEC != 400000000 || CONFIG_SYS_CLOCK_TICKS_PER_SEC != 10000
#error "Frozen baseline timer configuration mismatch"
#endif
__attribute__((section(".h1_baseline"), aligned(32)))
struct H1BaselineState h1BaselineState;
_Static_assert(sizeof(struct H1BaselineState) <= 65536, "baseline RAM budget");
_Static_assert(sizeof(struct H1BaselineEvent) == 12, "baseline event padding");
_Static_assert(H1_BASELINE_MAX_ORDERED_EVENTS >= 76, "complete event trace budget");
static const enum ethosu_pmu_event_type events[H1_BASELINE_EVENTS] = {
 ETHOSU_PMU_NPU_ACTIVE, ETHOSU_PMU_MAC_ACTIVE, ETHOSU_PMU_WD_ACTIVE,
 ETHOSU_PMU_WD_STALLED, ETHOSU_PMU_EXT_RD_TRAN_REQ_STALLED,
 ETHOSU_PMU_SRAM_RD_TRAN_REQ_STALLED, ETHOSU_PMU_SRAM_WR_TRAN_REQ_STALLED
};
void h1BaselineInit(void)
{
 memset(&h1BaselineState, 0, sizeof(h1BaselineState));
 h1BaselineState.cache_selector = SCB->CSSELR;
 if (h1BaselineState.cache_selector == 0) {
  uint32_t c = SCB->CCSIDR;
  h1BaselineState.cache_capacity_bytes =
   (1u << ((c & 7u) + 4u)) * (((c >> 3) & 1023u) + 1u) *
   (((c >> 13) & 32767u) + 1u);
 }
}
bool h1BaselineDiagnosticActive(void)
{
#if defined(H1_BASELINE_V2_INSTRUMENTATION)
 return h1BaselineState.running && h1BaselineState.mode != H1_BASELINE_ACCEPTANCE;
#else
 return false;
#endif
}
void h1BaselineBeginCampaign(uint32_t mode, uint32_t sequence)
{
 struct H1BaselineTensorMap maps[2];
 memcpy(maps, h1BaselineState.tensors, sizeof(maps));
 h1BaselineInit();
 memcpy(h1BaselineState.tensors, maps, sizeof(maps));
 h1BaselineState.mode = mode;
 h1BaselineState.running = 1;
 h1BaselineState.campaign_sequence = sequence;
 h1BaselineState.requested_samples = mode == H1_BASELINE_ACCEPTANCE ? 100 :
  mode == H1_BASELINE_OBSERVER ? 1 : 20;
 h1BaselineState.clock_hz = sys_clock_hw_cycles_per_sec();
 h1BaselineState.campaign_start = k_cycle_get_64();
 if (h1BaselineState.clock_hz != 400000000 || !h1BaselineState.cache_capacity_bytes)
  h1BaselineState.error = 1;
}
void h1BaselineBeginRun(int32_t index)
{
 h1BaselineState.current = NULL;
 if (h1BaselineDiagnosticActive()) {
  struct H1BaselineDiagnostic *p = index < 0 ? &h1BaselineState.warmup :
   &h1BaselineState.diagnostic[index];
  memset(p, 0, sizeof(*p));
  h1BaselineState.current = p;
 }
}
void h1BaselineEndRun(int32_t index, uint64_t start, uint64_t end,
 const struct H1RuntimeProfile *profile, uint32_t sequence, uint32_t status,
 const uint32_t crc[7], bool success)
{
 if (!h1LifecycleReuseReady() || !success || end <= start || !profile->valid || profile->clock_hz != 400000000 ||
     profile->backbone.command_count != 1 || profile->backbone.irq_count != 1 ||
     profile->classifier.command_count != 1 || profile->classifier.irq_count != 1 ||
     profile->backbone.lifecycle.copy_count != 0 ||
     profile->classifier.lifecycle.copy_count != 0 ||
     profile->backbone.lifecycle.runtime_init_count != 0 ||
     profile->classifier.lifecycle.runtime_init_count != 0)
  h1BaselineState.error = 2;
 if (!h1BaselineState.first_run_sequence) h1BaselineState.first_run_sequence = sequence;
 h1BaselineState.last_run_sequence = sequence;
 if (index >= 0) {
  h1BaselineState.samples[index] = end - start;
  memcpy(h1BaselineState.boundary_crc[index], crc, 7 * sizeof(uint32_t));
  ++h1BaselineState.measured_completed;
 } else ++h1BaselineState.warmups_completed;
 struct H1BaselineDiagnostic *p = h1BaselineState.current;
 if (p) {
  p->primary_start = start; p->primary_end = end;
  p->run_sequence = sequence; p->status = status;
  memcpy(&p->profile, profile, sizeof(*profile));
  p->stages[0] = p->spectral_cycles;
  p->stages[1] = p->mel_cycles;
  p->stages[2] = p->frontend_end - p->frontend_start - p->spectral_cycles -
   p->mel_cycles + p->quantize_end - p->quantize_start;
  p->stages[3] = profile->backbone.command_start_cycles - p->quantize_end;
  p->stages[4] = profile->backbone.irq_entry_cycles - profile->backbone.command_start_cycles;
  p->stages[5] = p->gem_start - profile->backbone.irq_entry_cycles;
  p->stages[6] = p->gem_end - p->gem_start;
  p->stages[7] = p->bridge_end - p->bridge_start;
  p->stages[8] = profile->classifier.command_start_cycles - p->bridge_end;
  p->stages[9] = profile->classifier.irq_entry_cycles - profile->classifier.command_start_cycles;
  p->stages[10] = end - profile->classifier.irq_entry_cycles;
  p->stages[11] = end - start;
  uint64_t sum = 0;
  for (unsigned i = 0; i < 11; ++i) sum += p->stages[i];
  if (sum > p->stages[11] || p->cache_count > H1_BASELINE_MAX_CACHE)
   h1BaselineState.error = 3;
  else p->residual_cycles = p->stages[11] - sum;
  if (h1BaselineState.mode == H1_BASELINE_PMU)
   for (unsigned i = 0; i < 2; ++i)
    if (!p->pmu[i].configured || p->pmu[i].snapshots != 2 ||
        p->pmu[i].overflow || p->pmu[i].after_cycles <= p->pmu[i].before_cycles)
     h1BaselineState.error = 4;
 }
 h1BaselineState.current = NULL;
}
void h1BaselineEndCampaign(void)
{
 h1BaselineState.campaign_end = k_cycle_get_64();
 h1BaselineState.running = 0;
 h1BaselineState.last_mode = h1BaselineState.mode;
 h1BaselineState.mode = 0;
}
void h1BaselineSpectralGroupBegin(void)
{
 if (h1BaselineDiagnosticActive()) h1BaselineState.spectral_group_start = k_cycle_get_64();
}
void h1BaselineSpectralGroupEnd(void)
{
 if (h1BaselineState.current)
  h1BaselineState.current->spectral_cycles += k_cycle_get_64() - h1BaselineState.spectral_group_start;
}
void h1BaselineMelCycles(uint64_t cycles)
{
 if (h1BaselineState.current) h1BaselineState.current->mel_cycles = cycles;
}
void h1BaselineMark(uint32_t marker, uint64_t cycles)
{
 struct H1BaselineDiagnostic *p = h1BaselineState.current;
 if (!p) return;
 switch (marker) {
 case 0: p->frontend_start = cycles; break; case 1: p->frontend_end = cycles; break;
 case 2: p->quantize_start = cycles; break; case 3: p->quantize_end = cycles; break;
 case 4: p->gem_start = cycles; break; case 5: p->gem_end = cycles; break;
 case 6: p->bridge_start = cycles; break; case 7: p->bridge_end = cycles; break;
 }
}
void h1BaselineTensorBind(uint32_t stage, uint32_t input, uint32_t input_bytes,
 uint32_t output, uint32_t output_bytes, uint32_t arena_used_bytes)
{
 if (h1BaselineState.running && h1BaselineState.mode == H1_BASELINE_ACCEPTANCE) return;
 h1BaselineState.npu_stage = stage;
 struct H1BaselineTensorMap *p = &h1BaselineState.tensors[stage];
 if (p->input && (p->input != input || p->output != output ||
     p->arena_used_bytes != arena_used_bytes)) h1BaselineState.error = 5;
 p->input = input; p->input_bytes = input_bytes;
 p->output = output; p->output_bytes = output_bytes; p->arena_used_bytes = arena_used_bytes;
}
void ethosu_inference_begin(struct ethosu_driver *drv, void *arg)
{
 (void)arg;
 if (h1BaselineState.mode != H1_BASELINE_PMU) return;
 h1BaselineState.pmu_driver = drv;
 struct H1BaselinePmu *p = &h1BaselineState.current->pmu[h1BaselineState.npu_stage];
 if (ETHOSU_PMU_Get_NumEventCounters() != 8) { h1BaselineState.error = 6; return; }
 ETHOSU_PMU_Enable(drv);
 ETHOSU_PMU_CNTR_Disable(drv, UINT32_MAX);
 ETHOSU_PMU_CYCCNT_Reset(drv); ETHOSU_PMU_EVCNTR_ALL_Reset(drv);
 ETHOSU_PMU_Set_CNTR_OVS(drv, UINT32_MAX);
 for (unsigned i = 0; i < H1_BASELINE_EVENTS; ++i) {
  ETHOSU_PMU_Set_EVTYPER(drv, i, events[i]);
  if (ETHOSU_PMU_Get_EVTYPER(drv, i) != events[i]) h1BaselineState.error = 7;
 }
 ETHOSU_PMU_Set_EVTYPER(drv, 7, ETHOSU_PMU_NO_EVENT);
 p->configured = h1BaselineState.error == 0;
}
void h1BaselineCommandSnapshot(void)
{
 if (h1BaselineState.mode != H1_BASELINE_PMU || !h1BaselineState.pmu_driver) return;
 struct ethosu_driver *drv = h1BaselineState.pmu_driver;
 struct H1BaselinePmu *p = &h1BaselineState.current->pmu[h1BaselineState.npu_stage];
 p->before_cycles = ETHOSU_PMU_Get_CCNTR(drv);
 for (unsigned i = 0; i < H1_BASELINE_EVENTS; ++i) p->before[i] = ETHOSU_PMU_Get_EVCNTR(drv, i);
 ETHOSU_PMU_CNTR_Enable(drv, ETHOSU_PMU_CCNT_Msk | 0x7fu);
 ++p->snapshots;
}
void h1BaselineIrqSnapshot(void)
{
 if (h1BaselineState.mode != H1_BASELINE_PMU || !h1BaselineState.pmu_driver) return;
 struct ethosu_driver *drv = h1BaselineState.pmu_driver;
 struct H1BaselinePmu *p = &h1BaselineState.current->pmu[h1BaselineState.npu_stage];
 ETHOSU_PMU_CNTR_Disable(drv, UINT32_MAX);
 p->after_cycles = ETHOSU_PMU_Get_CCNTR(drv);
 for (unsigned i = 0; i < H1_BASELINE_EVENTS; ++i) p->after[i] = ETHOSU_PMU_Get_EVCNTR(drv, i);
 p->overflow = ETHOSU_PMU_Get_CNTR_OVS(drv); ++p->snapshots;
}
void ethosu_inference_end(struct ethosu_driver *drv, void *arg)
{
 (void)arg;
 if (h1BaselineState.mode == H1_BASELINE_PMU && h1BaselineState.pmu_driver == drv) {
  ETHOSU_PMU_Disable(drv); h1BaselineState.pmu_driver = NULL;
 }
}
/* A single IRQ-serialized publication defines sequence and timestamp order.
 * The lock covers recorder stores only, never production cache maintenance. */
static uint64_t record_event_locked(struct H1BaselineDiagnostic *p,
 uint32_t kind, uint32_t value)
{
 if (p->event_count >= H1_BASELINE_MAX_ORDERED_EVENTS) {
  h1BaselineState.error = 10; return 0;
 }
 const uint64_t now = k_cycle_get_64();
 if (p->event_count && now <= p->events[p->event_count - 1].cycles)
  h1BaselineState.error = 11;
 struct H1BaselineEvent *e = &p->events[p->event_count++];
 e->cycles = now; e->kind = kind; e->stage = h1BaselineState.npu_stage;
 e->value = value;
 return now;
}
void h1BaselineObserve(uint32_t kind, uint32_t value)
{
 struct H1BaselineDiagnostic *p = h1BaselineState.current;
 if (!p) return;
 unsigned key = irq_lock();
 record_event_locked(p, kind, value);
 irq_unlock(key);
}
void h1BaselineStageBegin(uint32_t stage)
{
 struct H1BaselineDiagnostic *p = h1BaselineState.current;
 if (!p) return;
 unsigned key = irq_lock();
 h1BaselineState.npu_stage = stage;
 record_event_locked(p, H1_EVENT_LIFECYCLE_STAGE_BEGIN, 0);
 irq_unlock(key);
}
void h1BaselineCacheSelector(uint32_t mask, uint32_t base_index)
{
 if (!h1BaselineState.current) return;
 h1BaselineState.active_cache_mask = mask;
 h1BaselineState.active_cache_base_index = base_index;
}
struct H1BaselineCache *h1BaselineCacheBegin(uint32_t *address, uint32_t bytes,
 uint32_t flags, uint32_t begin_event)
{
 struct H1BaselineDiagnostic *p = h1BaselineState.current;
 if (!p) return NULL;
 unsigned key = irq_lock();
 if (p->cache_count >= H1_BASELINE_MAX_CACHE) {
  h1BaselineState.error = 8; irq_unlock(key); return NULL;
 }
 const uint32_t index = p->cache_count++;
 struct H1BaselineCache *c = &p->cache[index];
 c->stage = h1BaselineState.npu_stage;
 c->address = (uint32_t)(uintptr_t)address; c->requested_bytes = bytes;
 c->rounded_address = c->address & ~31u;
 c->rounded_bytes = ((c->address + bytes + 31u) & ~31u) - c->rounded_address;
 c->flags = flags;
 c->maintained_bytes = flags & H1_BASELINE_CACHE_WHOLE ?
  h1BaselineState.cache_capacity_bytes : flags & H1_BASELINE_CACHE_RANGE ?
  c->rounded_bytes : 0;
 c->mask = flags & H1_BASELINE_CACHE_GUARD ? 0 : h1BaselineState.active_cache_mask;
 c->base_index = flags & H1_BASELINE_CACHE_GUARD ? UINT32_MAX :
  h1BaselineState.active_cache_base_index;
 c->start_cycles = record_event_locked(p, begin_event, index);
 irq_unlock(key);
 return c;
}
void h1BaselineCacheEnd(struct H1BaselineCache *c, uint32_t end_event)
{
 if (!c) return;
 unsigned key = irq_lock();
 struct H1BaselineDiagnostic *p = h1BaselineState.current;
 c->end_cycles = record_event_locked(p, end_event, (uint32_t)(c - p->cache));
 irq_unlock(key);
}
void h1BaselineGuardInvalidate(uint32_t address, uint32_t bytes)
{
 (void)h1BaselineCacheBegin((uint32_t *)(uintptr_t)address, bytes,
  H1_BASELINE_CACHE_INVALIDATE | H1_BASELINE_CACHE_RANGE | H1_BASELINE_CACHE_GUARD,
  H1_EVENT_POST_COMPLETION_CACHE_BEGIN);
}
void h1BaselineGuardInvalidateDone(void)
{
 struct H1BaselineDiagnostic *p = h1BaselineState.current;
 if (p && p->cache_count)
  h1BaselineCacheEnd(&p->cache[p->cache_count - 1], H1_EVENT_POST_COMPLETION_CACHE_END);
}

uint32_t h1BaselinePmuCounters(void)
{
 return ETHOSU_PMU_Get_NumEventCounters();
}
```

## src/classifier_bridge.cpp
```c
// SPDX-FileCopyrightText: 2026 Taras Kuchynskyy
// SPDX-License-Identifier: Apache-2.0
#include "classifier_bridge.hpp"
#include "h1_contract.h"

#include <cstring>
#include <limits>

namespace birdnet::h1 {
namespace {
void saturated(bool negative, int16_t &output, int8_t &saturation)
{
	output = negative ? INT16_MIN : INT16_MAX;
	saturation = negative ? -1 : 1;
}
} // namespace

bool quantizeClassifierInputBits(uint32_t sourceBits, uint32_t scaleBits,
				 int16_t &output, int8_t &saturation)
{
	const uint32_t sourceExponent = (sourceBits >> 23) & 255u;
	const uint32_t scaleExponent = (scaleBits >> 23) & 255u;
	if (sourceExponent == 255u || scaleExponent == 255u ||
	    (scaleBits >> 31) != 0u || (scaleBits & UINT32_C(0x7fffffff)) == 0u) {
		return false;
	}
	const bool negative = (sourceBits >> 31) != 0u;
	uint64_t numerator = sourceBits & UINT32_C(0x007fffff);
	uint64_t denominator = scaleBits & UINT32_C(0x007fffff);
	if (sourceExponent != 0u) {
		numerator |= UINT64_C(0x00800000);
	}
	if (scaleExponent != 0u) {
		denominator |= UINT64_C(0x00800000);
	}
	if (numerator == 0u) {
		output = 0; // Both signs of zero.
		saturation = 0;
		return true;
	}
	const int32_t sourcePower = sourceExponent == 0u
		? -149 : static_cast<int32_t>(sourceExponent) - 150;
	const int32_t scalePower = scaleExponent == 0u
		? -149 : static_cast<int32_t>(scaleExponent) - 150;
	const int32_t power = sourcePower - scalePower;
	const uint64_t maximum = std::numeric_limits<uint64_t>::max();
	if (power >= 0) {
		const uint32_t shift = static_cast<uint32_t>(power);
		if (shift >= 64u || numerator > (maximum >> shift)) {
			// Exact numerator >= 2^64, denominator < 2^24:
			// exact quotient > 2^40. Its RNE result necessarily saturates.
			saturated(negative, output, saturation);
			return true;
		}
		numerator <<= shift;
	} else {
		const uint32_t shift = static_cast<uint32_t>(-power);
		if (shift >= 64u || denominator > (maximum >> shift)) {
			// Exact denominator >= 2^64, numerator < 2^24:
			// exact quotient < 2^-40, so its RNE result is exactly zero.
			output = 0;
			saturation = 0;
			return true;
		}
		denominator <<= shift;
	}
	uint64_t rounded = numerator / denominator;
	const uint64_t remainder = numerator % denominator;
	// Compare 2*remainder to denominator without overflowing either integer.
	const uint64_t complement = denominator - remainder;
	if (remainder > complement ||
	    (remainder == complement && (rounded & 1u) != 0u)) {
		if (rounded == maximum) {
			saturated(negative, output, saturation);
			return true;
		}
		++rounded;
	}
	const uint64_t limit = negative ? UINT64_C(32768) : UINT64_C(32767);
	if (rounded > limit) {
		saturated(negative, output, saturation);
	} else {
		const int32_t magnitude = static_cast<int32_t>(rounded);
		output = static_cast<int16_t>(negative ? -magnitude : magnitude);
		saturation = 0;
	}
	return true;
}

bool quantizeClassifierInput(const float *input, int16_t *output, size_t elements,
			   size_t &saturatedLow, size_t &saturatedHigh)
{
	static_assert(sizeof(float) == sizeof(uint32_t) &&
		      std::numeric_limits<float>::is_iec559,
		      "H1 bridge requires IEEE-754 binary32 storage");
	static_assert(H1_QUANT_ZERO_POINT == 0, "H1 bridge requires zero point 0");
	if (input == nullptr || output == nullptr) {
		return false;
	}
	saturatedLow = 0;
	saturatedHigh = 0;
	for (size_t index = 0; index < elements; ++index) {
		uint32_t bits;
		std::memcpy(&bits, &input[index], sizeof(bits));
		int8_t saturation;
		if (!quantizeClassifierInputBits(bits, H1_CLASSIFIER_INPUT_SCALE_BITS,
					 output[index], saturation)) {
			return false;
		}
		saturatedLow += saturation < 0;
		saturatedHigh += saturation > 0;
	}
	return true;
}

} // namespace birdnet::h1
```

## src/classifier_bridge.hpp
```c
// SPDX-FileCopyrightText: 2026 Taras Kuchynskyy
// SPDX-License-Identifier: Apache-2.0
#pragma once

#include <cstddef>
#include <cstdint>

#define H1_BRIDGE_POLICY_SHA256 \
  "67010defc48ed1772ee975b9dd3fc53213198f0b0deca26964e7af579af80087"

namespace birdnet::h1 {

// Exact finite binary32 ratio, nearest-even, then INT16 saturation. Invalid
// (nonfinite source or nonpositive/nonfinite scale) inputs return false without
// defining a quantized code. Saturation is -1, 0, or +1 after rounding.
bool quantizeClassifierInputBits(uint32_t sourceBits, uint32_t scaleBits,
				 int16_t &output, int8_t &saturation);

// Ordinary production bridge: frozen classifier scale and zero point 0.
bool quantizeClassifierInput(const float *input, int16_t *output, size_t elements,
			   size_t &saturatedLow, size_t &saturatedHigh);

} // namespace birdnet::h1
```
